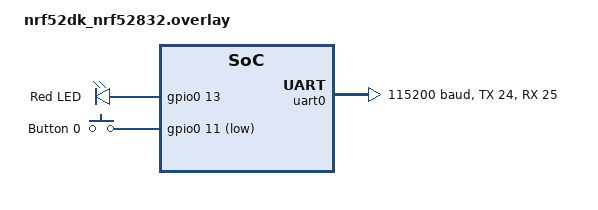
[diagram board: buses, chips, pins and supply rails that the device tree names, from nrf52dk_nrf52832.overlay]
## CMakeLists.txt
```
cmake_minimum_required(VERSION 3.20.0)
find_package(Zephyr REQUIRED HINTS $ENV{ZEPHYR_BASE})
project(nrf52832_led_uart)

target_sources(app PRIVATE src/main.c)
```

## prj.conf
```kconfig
# Project Configuration for nRF52832 with LED and UART

# Enable GPIO support
CONFIG_GPIO=y

# Enable UART support
CONFIG_UART_CONSOLE=y
CONFIG_SERIAL=y

# Set log level
CONFIG_LOG=y
CONFIG_LOG_BACKEND_UART=y
CONFIG_LOG_DEFAULT_LEVEL=3

# Enable threading
CONFIG_THREAD_STACK_INFO=y
CONFIG_THREAD_NAME=y

# Heap configuration
CONFIG_HEAP_MEM_POOL_SIZE=2048

# Enable printk for easier debugging
CONFIG_PRINTK=y
CONFIG_CONSOLE=y
CONFIG_UART_CONSOLE_ON_DEV_NAME="UART_0"
```

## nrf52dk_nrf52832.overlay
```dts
/*
 * Device Tree Overlay for nRF52832
 * LED on GPIO P0.13
 * UART on P0.24 (TX) and P0.25 (RX)
 */

/ {
	aliases {
		led0 = &led0;
		sw0 = &button0;
	};

	leds {
		compatible = "gpio-leds";
		led0: led_0 {
			gpios = <&gpio0 13 GPIO_ACTIVE_HIGH>;
			label = "Red LED";
		};
	};

	buttons {
		compatible = "gpio-keys";
		button0: button_0 {
			gpios = <&gpio0 11 (GPIO_PULL_UP | GPIO_ACTIVE_LOW)>;
			label = "Button 0";
		};
	};
};

&uart0 {
	status = "okay";
	current-speed = <115200>;
	tx-pin = <24>;
	rx-pin = <25>;
};

&gpio0 {
	status = "okay";
};
```

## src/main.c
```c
/*
 * Copyright (c) 2024
 * nRF52832 LED and UART Demo Application
 */

#include <zephyr/kernel.h>
#include <zephyr/device.h>
#include <zephyr/drivers/gpio.h>
#include <zephyr/drivers/uart.h>
#include <zephyr/sys/printk.h>

/* Define LED device */
#define LED0_NODE DT_ALIAS(led0)

static const struct gpio_dt_spec led = GPIO_DT_SPEC_GET(LED0_NODE, gpios);

/* UART device */
const struct device *uart_dev = DEVICE_DT_GET(DT_NODELABEL(uart0));

/* Check if LED device exists */
#if !DT_NODE_EXISTS(LED0_NODE)
#error "Unsupported board: led0 devicetree alias is not defined"
#endif

/* UART callback for data reception */
static void uart_cb(const struct device *dev, struct uart_event *evt, void *user_data)
{
	if (evt->type == UART_RX_RDY) {
		printk("UART RX Ready\n");
	}
}

void main(void)
{
	int ret;

	printk("nRF52832 LED and UART Demo Started\n");

	/* Verify LED GPIO device is ready */
	if (!gpio_is_ready_dt(&led)) {
		printk("LED GPIO device is not ready\n");
		return;
	}

	/* Configure LED GPIO pin as output */
	ret = gpio_pin_configure_dt(&led, GPIO_OUTPUT_INACTIVE);
	if (ret < 0) {
		printk("Failed to configure LED GPIO pin: %d\n", ret);
		return;
	}

	printk("LED configured on GPIO P0.13\n");

	/* Verify UART device is ready */
	if (!device_is_ready(uart_dev)) {
		printk("UART device is not ready\n");
		return;
	}

	printk("UART initialized on P0.24 (TX) and P0.25 (RX)\n");
	printk("UART Baudrate: 115200\n\n");

	/* Main loop: blink LED */
	int counter = 0;
	while (1) {
		/* Toggle LED */
		ret = gpio_pin_toggle_dt(&led);
		if (ret < 0) {
			printk("Failed to toggle LED: %d\n", ret);
			return;
		}

		counter++;
		printk("[%d] LED toggled. LED is now %s\n", 
		       counter, 
		       gpio_pin_get_dt(&led) ? "ON" : "OFF");

		/* Wait 1 second */
		k_msleep(1000);
	}
}
```

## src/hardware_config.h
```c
/**
 * @file hardware_config.h
 * @brief Hardware Configuration Definitions for nRF52832
 *
 * This file contains easy-to-modify hardware pin and peripheral definitions.
 * Modify these values to change pin assignments without editing main.c
 */

#ifndef HARDWARE_CONFIG_H
#define HARDWARE_CONFIG_H

/* ============================================================================
 * LED Configuration
 * ========================================================================== */

/**
 * @defgroup LED_CONFIG LED Configuration
 * @brief LED hardware configuration
 * @{
 */

/** @brief LED GPIO Port (0 for GPIO Port 0) */
#define LED_PORT 0

/** @brief LED Pin Number (13 = P0.13) */
#define LED_PIN 13

/** @brief LED Active Level (1 = Active High, 0 = Active Low) */
#define LED_ACTIVE_HIGH 1

/** @brief Initial LED State (1 = ON, 0 = OFF) */
#define LED_INITIAL_STATE 0

/** @} */

/* ============================================================================
 * UART Configuration
 * ========================================================================== */

/**
 * @defgroup UART_CONFIG UART Configuration
 * @brief UART hardware configuration
 * @{
 */

/** @brief UART Instance (0 = UART0) */
#define UART_INSTANCE 0

/** @brief UART TX Pin (24 = P0.24) */
#define UART_TX_PIN 24

/** @brief UART RX Pin (25 = P0.25) */
#define UART_RX_PIN 25

/** @brief UART Baud Rate (bits per second) */
#define UART_BAUDRATE 115200

/** @brief UART Data Bits (typically 8) */
#define UART_DATA_BITS 8

/** @brief UART Stop Bits (typically 1) */
#define UART_STOP_BITS 1

/** @brief UART Parity (0 = None, 1 = Odd, 2 = Even) */
#define UART_PARITY 0

/** @} */

/* ============================================================================
 * Application Timing Configuration
 * ========================================================================== */

/**
 * @defgroup TIMING_CONFIG Timing Configuration
 * @brief Application timing parameters
 * @{
 */

/** @brief LED Blink Period in milliseconds */
#define LED_BLINK_PERIOD_MS 1000

/** @brief LED ON time in milliseconds (when period is 2000ms: 1000ms ON, 1000ms OFF) */
#define LED_ON_TIME_MS (LED_BLINK_PERIOD_MS / 2)

/** @brief LED OFF time in milliseconds */
#define LED_OFF_TIME_MS (LED_BLINK_PERIOD_MS / 2)

/** @} */

/* ============================================================================
 * Debug Configuration
 * ========================================================================== */

/**
 * @defgroup DEBUG_CONFIG Debug Configuration
 * @brief Debug and logging settings
 * @{
 */

/** @brief Enable verbose debug output (1 = enabled, 0 = disabled) */
#define DEBUG_VERBOSE 1

/** @brief Print LED toggle counter (1 = yes, 0 = no) */
#define PRINT_COUNTER 1

/** @brief Print GPIO state on each toggle (1 = yes, 0 = no) */
#define PRINT_GPIO_STATE 1

/** @} */

/* ============================================================================
 * Feature Configuration
 * ========================================================================== */

/**
 * @defgroup FEATURE_CONFIG Feature Configuration
 * @brief Feature enable/disable flags
 * @{
 */

/** @brief Enable LED functionality (1 = enabled, 0 = disabled) */
#define ENABLE_LED 1

/** @brief Enable UART logging (1 = enabled, 0 = disabled) */
#define ENABLE_UART 1

/** @brief Enable Button functionality (1 = enabled, 0 = disabled) */
#define ENABLE_BUTTON 0

/** @brief Enable PWM LED fading (1 = enabled, 0 = disabled) */
#define ENABLE_PWM_FADE 0

/** @} */

#endif /* HARDWARE_CONFIG_H */
```
